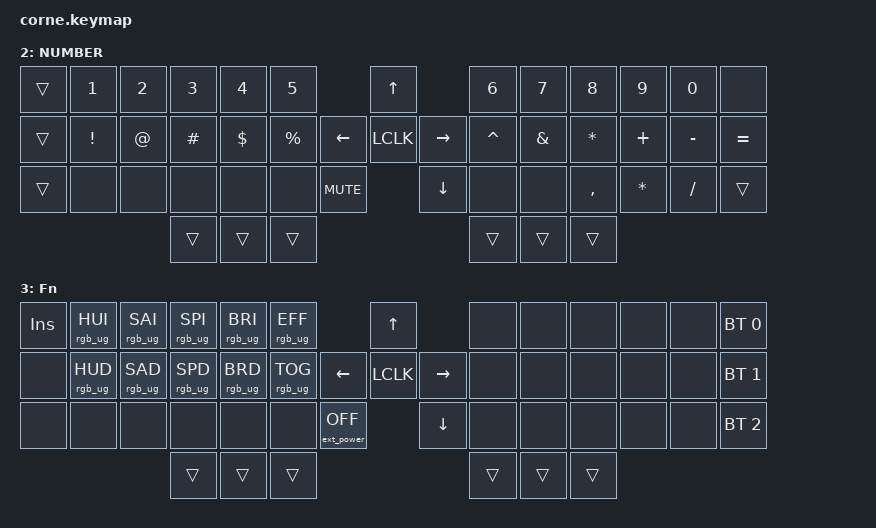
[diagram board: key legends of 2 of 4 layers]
#define ZMK_POINTING_DEFAULT_MOVE_VAL 1200  // 600
#define ZMK_POINTING_DEFAULT_SCRL_VAL 25   // 10

#include <input/processors.dtsi>
#include <zephyr/dt-bindings/input/input-event-codes.h>
#include <behaviors.dtsi>
#include <dt-bindings/zmk/bt.h>
#include <dt-bindings/zmk/keys.h>
#include <dt-bindings/zmk/outputs.h>
#include <dt-bindings/zmk/pointing.h>
#include <dt-bindings/zmk/rgb.h>

&mmv_input_listener { input-processors = <&zip_xy_scaler 2 1>; };

&msc_input_listener { input-processors = <&zip_scroll_scaler 2 1>; };

&msc {
    acceleration-exponent = <0>;      // 0
    time-to-max-speed-ms = <100>;       // 300
    delay-ms = <0>;                   // 0
};

&mmv {
    time-to-max-speed-ms = <500>;
    acceleration-exponent = <0>;
    trigger-period-ms = <16>;
};

&soft_off { hold-time-ms = <2000>; };

/ {
    behaviors {
    };

    rgb_encoder: rgb_encoder {
        compatible = "zmk,behavior-sensor-rotate";
        #sensor-binding-cells = <0>;
        bindings = <&rgb_ug RGB_BRI>, <&rgb_ug RGB_BRD>;
    };

    scroll_encoder: scroll_encoder {
        compatible = "zmk,behavior-sensor-rotate";
        #sensor-binding-cells = <0>;
        bindings = <&msc SCRL_DOWN>, <&msc SCRL_UP>;

        tap-ms = <100>;
    };

    combos {
        compatible = "zmk,combos";

        softoff {
            bindings = <&soft_off>;
            key-positions = <1 15 29>;
        };
    };

    keymap {
        compatible = "zmk,keymap";

        default_layer {
            display-name = "QWERTY";
            bindings = <
&kp TAB                    &kp Q                      &kp W                      &kp E                      &kp R                      &kp T                                                                            &kp UP                                                &kp Y                      &kp U                      &kp I                      &kp O                      &kp P                      &kp LALT L
&kp CAP                    &kp A                      &kp S                      &kp D                      &kp F                      &kp G                                                 &kp LEFT                   &kp LCLK                   &kp RIGHT                  &kp H                      &kp J                      &kp K                      &kp L                      &kp SEMI                   &kp ENTER
&kp LSHIFT                 &kp Z                      &kp X                      &kp C                      &kp V                      &kp B                      &kp C_MUTE                                            &kp DOWN                                              &kp N                      &kp M                      &kp COMMA                  &kp DOT                    &kp FSLH                   &kp RSHIFT
                                                                                 &kp LGUI                   &kp LCTRL                  &kp LALT                                                                                                                               &mo 1                      &lt 3 SPACE                &mo 2
            >;

            sensor-bindings = <&inc_dec_kp C_VOLUME_UP C_VOLUME_DOWN>;
        };

        symbol_layer {
            display-name = "SYMBOL";
            bindings = <
&trans                      &kp LCTRL LALT K          &kp LCTRL LALT E          &kp LCTRL LALT M          &kp LCTRL LALT S          &kp LCTRL LALT F                                                              &kp LCTRL UP                                        &none                     &kp LPAR                  &kp RPAR                  &none                     &none                     &trans
&kp LCTRL CAPS              &kp LCTRL LALT A          &kp LCTRL LALT X          &kp LCTRL LALT SPACE      &kp LCTRL LALT P          &kp LCTRL LALT G                                    &kp LCTRL LEFT            &kp LCLK                  &kp LCTRL RIGHT           &none                     &kp LBRC                  &kp RBRC                  &kp GRAVE                 &kp SQT                   &kp DQT
&trans                      &kp LCTRL LALT Z          &kp LCTRL LALT C          &kp LCTRL LALT N          &kp LCTRL LALT G          &kp LGUI LCTRL C          &kp C_MUTE                                          &kp LCTRL DOWN                                      &none                     &kp LBKT                  &kp RBKT                  &kp PIPE                  &kp BSLH                  &trans
                                                                                &trans                    &trans                    &trans                                                                                                                            &trans                    &trans                    &trans
            >;  

            sensor-bindings = <&scroll_encoder>;
        };

        number_layer {
            display-name = "NUMBER";
            bindings = <
&trans                      &kp N1                     &kp N2                     &kp N3                     &kp N4                     &kp N5                                                                           &kp UP                                                &kp N6                     &kp N7                     &kp N8                     &kp N9                     &kp N0                     &none
&trans                      &kp EXCL                   &kp AT                     &kp HASH                   &kp DLLR                   &kp PRCNT                                             &kp LEFT                   &kp LCLK                   &kp RIGHT                  &kp CARET                  &kp AMPS                   &kp STAR                   &kp PLUS                   &kp MINUS                  &kp EQUAL
&trans                      &none                      &none                      &none                      &none                      &none                   &kp C_MUTE                                            &kp DOWN                                              &none                      &none                      &kp COMMA                  &kp STAR                   &kp FSLH                   &trans
                                                                                  &trans                     &trans                     &trans                                                                                                                                 &trans                     &trans                     &trans
            >;

            sensor-bindings = <&scroll_encoder>;
        };

        fn_layer {
            display-name = "Fn";
            bindings = <
&kp INSERT                 &rgb_ug RGB_HUI             &rgb_ug RGB_SAI             &rgb_ug RGB_SPI             &rgb_ug RGB_BRI             &rgb_ug RGB_EFF                                                                   &kp UP                                                &none                      &none                      &none                      &none                      &none                      &bt BT_SEL 0
&none                      &rgb_ug RGB_HUD             &rgb_ug RGB_SAD             &rgb_ug RGB_SPD             &rgb_ug RGB_BRD             &rgb_ug RGB_TOG                                        &kp LEFT                   &kp LCLK                   &kp RIGHT                  &none                      &none                      &none                      &none                      &none                      &bt BT_SEL 1
&none                      &none                       &none                       &none                       &none                       &none                       &ext_power EP_OFF                                     &kp DOWN                                              &none                      &none                      &none                      &none                      &none                      &bt BT_SEL 2
                                                                                   &trans                     &trans                      &trans                                                                                                                                   &trans                     &trans                     &trans
            >;

            sensor-bindings = <&scroll_encoder>;
        };
    };
};
